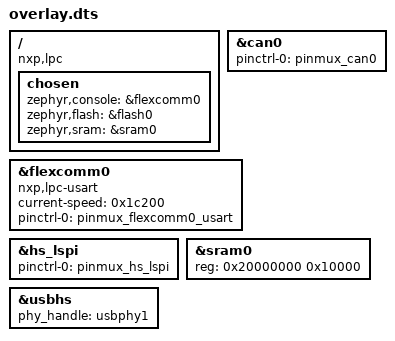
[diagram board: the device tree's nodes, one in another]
/ {
	compatible = "nxp,lpc", "nxp,lpc55xxx";
	chosen {
		zephyr,console = &flexcomm0;
		zephyr,flash = &flash0;
		zephyr,sram = &sram0;
	};
};
&can0{
	status = "okay";
	pinctrl-0 = < &pinmux_can0 >;
	pinctrl-names = "default";
};
&flexcomm0{
	compatible = "nxp,lpc-usart";
	status = "okay";
	current-speed = < 0x1c200 >;
	pinctrl-0 = < &pinmux_flexcomm0_usart >;
	pinctrl-names = "default";
};
&hs_lspi{
	status = "okay";
	pinctrl-0 = < &pinmux_hs_lspi >;
	pinctrl-names = "default";
};
&sram0{
	reg = < 0x20000000 0x10000 >;
};
&usbhs{
	status = "okay";
	phy_handle = < &usbphy1 >;
};
